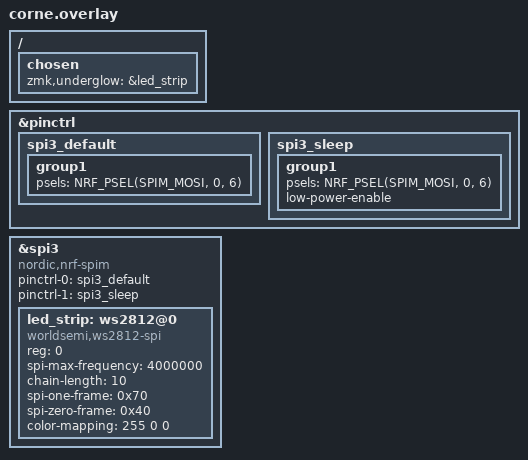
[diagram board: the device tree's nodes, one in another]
#include <dt-bindings/led/led.h>

&pinctrl {
    spi3_default: spi3_default {
        group1 {
            psels = <NRF_PSEL(SPIM_MOSI, 0, 6)>;
        };
    };

    spi3_sleep: spi3_sleep {
        group1 {
            psels = <NRF_PSEL(SPIM_MOSI, 0, 6)>;
            low-power-enable;
        };
    };
};

&spi3 {
    compatible = "nordic,nrf-spim";
    status = "okay";

    pinctrl-0 = <&spi3_default>;
    pinctrl-1 = <&spi3_sleep>;
    pinctrl-names = "default", "sleep";

    led_strip: ws2812@0 {
        compatible = "worldsemi,ws2812-spi";

        /* SPI */
        reg = <0>; /* ignored, but necessary for SPI bindings */
        spi-max-frequency = <4000000>;

        /* WS2812 */
        chain-length = <10>; /* arbitrary; change at will */
        spi-one-frame = <0x70>;
        spi-zero-frame = <0x40>;

        color-mapping = <255 0 0>;
    };
};

/ {
    chosen {
        zmk,underglow = &led_strip;
    };
};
